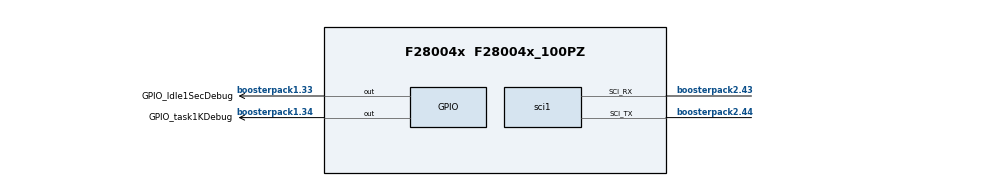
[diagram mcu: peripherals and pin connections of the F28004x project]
/**
 * @cliArgs --board "/boards/LAUNCHXL_F280049C" --device "F28004x" --part "F28004x_100PZ" --package "F28004x_100PZ" --context "system" --product "C2000WARE@26.00.00.00"
 * @versions {"tool":"1.27.1+4634"}
 */

/**
 * Import the modules used in this configuration.
 */
const cputimer  = scripting.addModule("/driverlib/cputimer.js", {}, false);
const cputimer1 = cputimer.addInstance();
const cputimer2 = cputimer.addInstance();
const gpio      = scripting.addModule("/driverlib/gpio.js", {}, false);
const gpio1     = gpio.addInstance();
const gpio2     = gpio.addInstance();
const sci       = scripting.addModule("/driverlib/sci.js", {}, false);
const sci1      = sci.addInstance();

/**
 * Write custom configuration values to the imported modules.
 */
cputimer1.enableInterrupt = true;
cputimer1.$name           = "CPUTIMER_TimeBase";
cputimer1.emulationMode   = "CPUTIMER_EMULATIONMODE_RUNFREE";
cputimer1.timerPeriod     = 4294967295;
cputimer1.timerPrescaler  = 9;

cputimer2.cputimerBase             = "CPUTIMER1_BASE";
cputimer2.$name                    = "CPUTIMER_TASK_1K";
cputimer2.enableInterrupt          = true;
cputimer2.registerInterrupts       = true;
cputimer2.timerPeriod              = 99999;
cputimer2.timerInt.enableInterrupt = true;

const default_warning = scripting.addModule("/driverlib/default_warning.js", {}, false);
scripting.suppress("Add the \'Device Support\' module in order to use Clock Tree tool and generate device support files\\. This suggestion can be ignored if not using the Clock Tree tool\\.", default_warning);

gpio1.direction         = "GPIO_DIR_MODE_OUT";
gpio1.writeInitialValue = true;
gpio1.$name             = "GPIO_task1KDebug";
gpio1.gpioPin.$assign   = "boosterpack1.34";

gpio2.$name           = "GPIO_Idle1SecDebug";
gpio2.direction       = "GPIO_DIR_MODE_OUT";
gpio2.gpioPin.$assign = "boosterpack1.33";

sci1.$hardware             = system.deviceData.board.components.XDS_UART.subComponents.XDS_SCI_INST1;
sci1.$name                 = "XDS_SCIA";
sci1.rxQual.$name          = "myGPIOQUAL0";
sci1.txQual.$name          = "myGPIOQUAL1";
sci1.sci.$assign           = "SCIA";
sci1.sci.sci_rxPin.$assign = "boosterpack2.43";
sci1.sci.sci_txPin.$assign = "boosterpack2.44";
